AUTOSAR XML (schema 00051)
package /SwComponentTypes
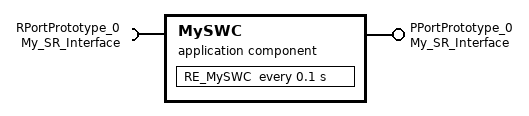
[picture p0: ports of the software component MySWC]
  application sw component type MySWC
    provide port PPortPrototype_0: provided-interface=My_SR_Interface
    require port RPortPrototype_0: required-interface=My_SR_Interface
    behavior SwcInternalBehavior_0: data-type-mapping=MyDataTypeMappingSet, supports-multiple-instantiation=true
      timing event TimingEvent_0: start-on-event=RE_MySWC, period=0.1
      runnable RE_MySWC: symbol=RE_MySWC_func
        data-read-access:
          access DRA_DE_MyDataElement_0: accessed-variable=RPortPrototype_0.DE_MyDataElement
        data-send-points:
          access DSP_DE_MyDataElement_0: accessed-variable=PPortPrototype_0.DE_MyDataElement
